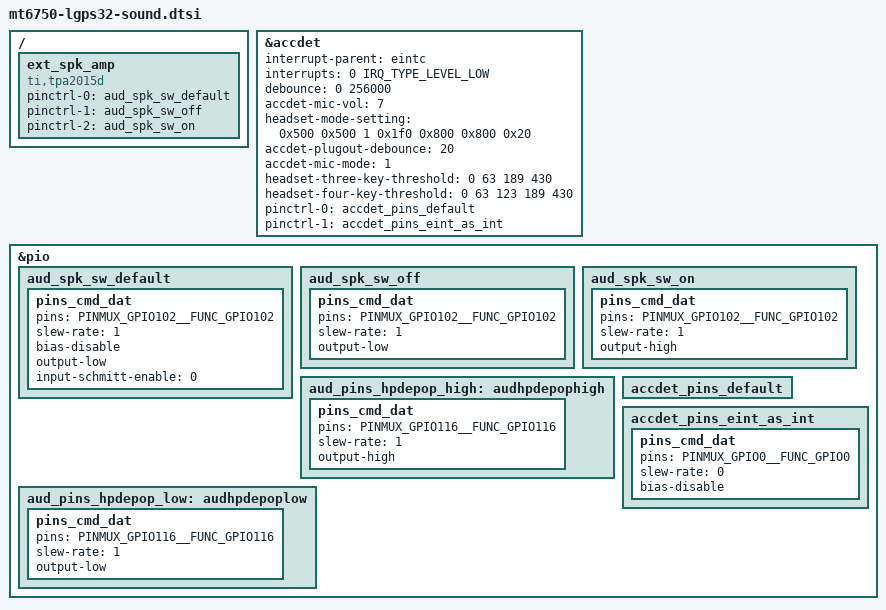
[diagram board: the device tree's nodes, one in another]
/*
 * LG Electronics LGP-S32 sound device tree source
 *
 * Copyright (c) 2016 LG Electronics Co., Ltd.
 *              http://www.lge.com
 *
 */

/ {
/* audio ext amp */
	ext_spk_amp {
		compatible = "ti,tpa2015d";
		status = "okay";
		pinctrl-names = "aud_spk_sw_default", "aud_spk_sw_off", "aud_spk_sw_on";
		pinctrl-0 = <&aud_spk_sw_default>;
		pinctrl-1 = <&aud_spk_sw_off>;
		pinctrl-2 = <&aud_spk_sw_on>;
	};

};

&accdet {
	interrupt-parent = <&eintc>;
	interrupts = <0 IRQ_TYPE_LEVEL_LOW>;
	debounce = <0 256000>;
	status = "okay";

	accdet-mic-vol = <7>;
	headset-mode-setting = <0x500 0x500 1 0x1f0 0x800 0x800 0x20>;
	accdet-plugout-debounce = <20>;
	/*1:ACC mode, 2:low cost without in bias, 6:low cost with in bias*/
	accdet-mic-mode = <1>;
	/*0--MD_MAX--UP_MAX--DW_MAX*/
	headset-three-key-threshold = <0 63 189 430>;
	/*0--MD_MAX--VOICE_MAX--UP_MAX--DW_MAX*/
	headset-four-key-threshold = <0 63 123 189 430>;

	pinctrl-names = "default", "state_eint_as_int";
	pinctrl-0 = <&accdet_pins_default>;
	pinctrl-1 = <&accdet_pins_eint_as_int>;
};

&pio {
/* audio ext amp */
	aud_spk_sw_default: aud_spk_sw_default {
		pins_cmd_dat {
			pins = <PINMUX_GPIO102__FUNC_GPIO102>;
			slew-rate = <1>; // output
			bias-disable; // output
			output-low;
			input-schmitt-enable = <0>;
		};
	};

	aud_spk_sw_off: aud_spk_sw_off {
		pins_cmd_dat {
			pins = <PINMUX_GPIO102__FUNC_GPIO102>;
			slew-rate = <1>; // output
			output-low;
		};
	};

	aud_spk_sw_on: aud_spk_sw_on {
		pins_cmd_dat {
			pins = <PINMUX_GPIO102__FUNC_GPIO102>;
			slew-rate = <1>; // output
			output-high;
		};
	};

/* HPH_AMP_SW */
	aud_pins_hpdepop_high: audhpdepophigh {
		pins_cmd_dat {
			pins = <PINMUX_GPIO116__FUNC_GPIO116>;
			slew-rate = <1>;
			output-high;
		};
	};

	aud_pins_hpdepop_low: audhpdepoplow {
		pins_cmd_dat {
			pins = <PINMUX_GPIO116__FUNC_GPIO116>;
			slew-rate = <1>;
			output-low;
		};
	};

/* accdet */
	accdet_pins_default: accdet_pins_default {
	};
	accdet_pins_eint_as_int: accdet_pins_eint_as_int {
		pins_cmd_dat {
			pins = <PINMUX_GPIO0__FUNC_GPIO0>;
			slew-rate = <0>;
			bias-disable;
		};
	};

};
